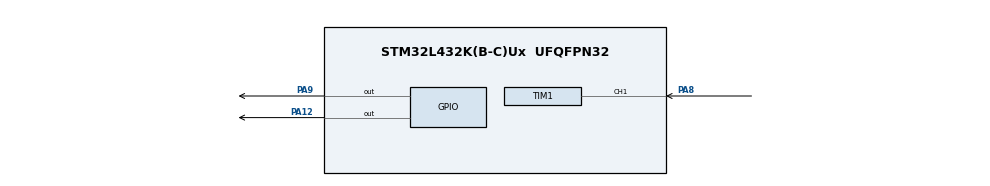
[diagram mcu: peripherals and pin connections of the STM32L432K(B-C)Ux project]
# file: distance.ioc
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Mcu.Family=STM32L4
Mcu.Name=STM32L432K(B-C)Ux
Mcu.Package=UFQFPN32
NVIC.PriorityGroup=NVIC_PRIORITYGROUP_4
NVIC.TIM1_CC_IRQn=true\:0\:0\:false\:false\:true\:true\:true
PA12.Signal=GPIO_Output
PA13\ (JTMS-SWDIO).Mode=Serial_Wire
PA13\ (JTMS-SWDIO).Signal=SYS_JTMS-SWDIO
PA14\ (JTCK-SWCLK).Mode=Serial_Wire
PA14\ (JTCK-SWCLK).Signal=SYS_JTCK-SWCLK
PA8.Signal=S_TIM1_CH1
PA9.Signal=GPIO_Output
ProjectManager.HeapSize=0x200
ProjectManager.StackSize=0x400
ProjectManager.TargetToolchain=MDK-ARM V5
RCC.HSE_VALUE=8000000
RCC.HSI48_VALUE=48000000
RCC.HSI_VALUE=16000000
RCC.LSE_VALUE=32768
RCC.MSI_VALUE=4000000
RCC.VCOOutputFreq_Value=32000000
SH.S_TIM1_CH1.0=TIM1_CH1,Input_Capture1_from_TI1
TIM1.Channel-Input_Capture1_from_TI1=TIM_CHANNEL_1
TIM1.Period=0xffff-1
TIM1.Prescaler=8-1
VP_TIM1_VS_ClockSourceINT.Mode=Internal
board=custom

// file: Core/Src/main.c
/* USER CODE BEGIN Header */
/**
  ******************************************************************************
  * @file           : main.c
  * @brief          : Main program body
  ******************************************************************************
  * @attention
  *
  * <h2><center>&copy; Copyright (c) 2021 STMicroelectronics.
  * All rights reserved.</center></h2>
  *
  * This software component is licensed by ST under BSD 3-Clause license,
  * the "License"; You may not use this file except in compliance with the
  * License. You may obtain a copy of the License at:
  *                        opensource.org/licenses/BSD-3-Clause
  *
  ******************************************************************************
  */
/* USER CODE END Header */
#include "main.h"

/* USER CODE BEGIN Includes */
#include "stdio.h"
#include "queue.h"
#include "taskApp2.h"
/* USER CODE END Includes */

/* USER CODE BEGIN PD */
#define TRIG_PIN  GPIO_PIN_9
#define TRIG_PORT GPIOA
/* USER CODE END PD */

int volatile countMsec =0;
int volatile countSec= 0;
int volatile R = 0;
int volatile Sysflag = 1;
int volatile  inverseDistance = 10;
extern q * delay_queue;

TIM_HandleTypeDef htim1;

void task_5_systick(void)
	{

	//__disable_irq();
	countMsec +=1;

	if ((countMsec %1000) == 0)
	{
		countMsec = 0;
		//Sysflag =1;
			t * current_p;
			t * deleted;

    current_p = delay_queue->head_of_queue;

    while(current_p!=NULL){
        current_p->delay -= 1;
        if(current_p->delay<=0)
				{
        	QueTask(current_p->f, current_p->priority);
        	delay_queue->head_of_queue = current_p->next_task;
					deleted = current_p;
					current_p = current_p->next_task;
					free (deleted);
					break;
        }
				else
				{
					current_p = current_p->next_task;
				}

    }
//		HAL_GPIO_WritePin(GPIOA, GPIO_PIN_12,GPIO_PIN_RESET);
	}

	//__enable_irq();
}
/* Task 5 Run the Buzz Relative to the Distance */
/* void task_5_Run_Buzz(void)
{
}*/

/* USER CODE END PV */

void SystemClock_Config(void);
static void MX_GPIO_Init(void);
static void MX_TIM1_Init(void);

int main(void)
{

  /* MCU Configuration--------------------------------------------------------*/

  /* Reset of all peripherals, Initializes the Flash interface and the Systick. */
  HAL_Init();

  /* Configure the system clock */
  SystemClock_Config();

  /* Initialize all configured peripherals */
  MX_GPIO_Init();
  MX_TIM1_Init();
  /* USER CODE BEGIN 2 */

	HAL_TIM_IC_Start_IT(&htim1, TIM_CHANNEL_1);
	init();
	QueTask(task_3_measure_distance, 1);
	QueTask(task_4_Buzz_sound, 2);

	/* USER CODE END 2 */

  /* Infinite loop */
  /* USER CODE BEGIN WHILE */
  while (1)
  {
		Dispatch();

    /* USER CODE END WHILE */

  }
}

void SystemClock_Config(void)
{
  RCC_OscInitTypeDef RCC_OscInitStruct = {0};
  RCC_ClkInitTypeDef RCC_ClkInitStruct = {0};

  /** Initializes the RCC Oscillators according to the specified parameters
  * in the RCC_OscInitTypeDef structure.
  */
  RCC_OscInitStruct.OscillatorType = RCC_OSCILLATORTYPE_MSI;
  RCC_OscInitStruct.MSIState = RCC_MSI_ON;
  RCC_OscInitStruct.MSICalibrationValue = 0;
  RCC_OscInitStruct.MSIClockRange = RCC_MSIRANGE_6;
  RCC_OscInitStruct.PLL.PLLState = RCC_PLL_NONE;
  if (HAL_RCC_OscConfig(&RCC_OscInitStruct) != HAL_OK)
  {
    Error_Handler();
  }
  /** Initializes the CPU, AHB and APB buses clocks
  */
  RCC_ClkInitStruct.ClockType = RCC_CLOCKTYPE_HCLK|RCC_CLOCKTYPE_SYSCLK
                              |RCC_CLOCKTYPE_PCLK1|RCC_CLOCKTYPE_PCLK2;
  RCC_ClkInitStruct.SYSCLKSource = RCC_SYSCLKSOURCE_MSI;
  RCC_ClkInitStruct.AHBCLKDivider = RCC_SYSCLK_DIV1;
  RCC_ClkInitStruct.APB1CLKDivider = RCC_HCLK_DIV1;
  RCC_ClkInitStruct.APB2CLKDivider = RCC_HCLK_DIV1;

  if (HAL_RCC_ClockConfig(&RCC_ClkInitStruct, FLASH_LATENCY_0) != HAL_OK)
  {
    Error_Handler();
  }
  /** Configure the main internal regulator output voltage
  */
  if (HAL_PWREx_ControlVoltageScaling(PWR_REGULATOR_VOLTAGE_SCALE1) != HAL_OK)
  {
    Error_Handler();
  }
}

static void MX_TIM1_Init(void)
{

  TIM_ClockConfigTypeDef sClockSourceConfig = {0};
  TIM_MasterConfigTypeDef sMasterConfig = {0};
  TIM_IC_InitTypeDef sConfigIC = {0};

  htim1.Instance = TIM1;
  htim1.Init.Prescaler = 8-1;
  htim1.Init.CounterMode = TIM_COUNTERMODE_UP;
  htim1.Init.Period = 0xffff-1;
  htim1.Init.ClockDivision = TIM_CLOCKDIVISION_DIV1;
  htim1.Init.RepetitionCounter = 0;
  htim1.Init.AutoReloadPreload = TIM_AUTORELOAD_PRELOAD_DISABLE;
  if (HAL_TIM_Base_Init(&htim1) != HAL_OK)
  {
    Error_Handler();
  }
  sClockSourceConfig.ClockSource = TIM_CLOCKSOURCE_INTERNAL;
  if (HAL_TIM_ConfigClockSource(&htim1, &sClockSourceConfig) != HAL_OK)
  {
    Error_Handler();
  }
  if (HAL_TIM_IC_Init(&htim1) != HAL_OK)
  {
    Error_Handler();
  }
  sMasterConfig.MasterOutputTrigger = TIM_TRGO_RESET;
  sMasterConfig.MasterOutputTrigger2 = TIM_TRGO2_RESET;
  sMasterConfig.MasterSlaveMode = TIM_MASTERSLAVEMODE_DISABLE;
  if (HAL_TIMEx_MasterConfigSynchronization(&htim1, &sMasterConfig) != HAL_OK)
  {
    Error_Handler();
  }
  sConfigIC.ICPolarity = TIM_INPUTCHANNELPOLARITY_RISING;
  sConfigIC.ICSelection = TIM_ICSELECTION_DIRECTTI;
  sConfigIC.ICPrescaler = TIM_ICPSC_DIV1;
  sConfigIC.ICFilter = 0;
  if (HAL_TIM_IC_ConfigChannel(&htim1, &sConfigIC, TIM_CHANNEL_1) != HAL_OK)
  {
    Error_Handler();
  }

}

static void MX_GPIO_Init(void)
{
  GPIO_InitTypeDef GPIO_InitStruct = {0};

  /* GPIO Ports Clock Enable */
  __HAL_RCC_GPIOA_CLK_ENABLE();

  /*Configure GPIO pin Output Level */
  HAL_GPIO_WritePin(GPIOA, GPIO_PIN_9|GPIO_PIN_12, GPIO_PIN_RESET);

  /*Configure GPIO pins : PA9 PA12 */
  GPIO_InitStruct.Pin = GPIO_PIN_9|GPIO_PIN_12;
  GPIO_InitStruct.Mode = GPIO_MODE_OUTPUT_PP;
  GPIO_InitStruct.Pull = GPIO_NOPULL;
  GPIO_InitStruct.Speed = GPIO_SPEED_FREQ_LOW;
  HAL_GPIO_Init(GPIOA, &GPIO_InitStruct);

}

void Error_Handler(void)
{
  __disable_irq();
  while (1)
  {
  }
}

/************************ (C) COPYRIGHT STMicroelectronics *****END OF FILE****/
